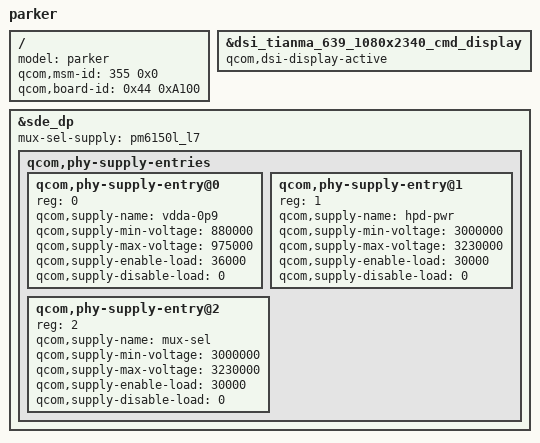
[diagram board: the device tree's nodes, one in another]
/* Copyright (c) 2019, The Linux Foundation. All rights reserved.
 *
 * This program is free software; you can redistribute it and/or modify
 * it under the terms of the GNU General Public License version 2 and
 * only version 2 as published by the Free Software Foundation.
 *
 * This program is distributed in the hope that it will be useful,
 * but WITHOUT ANY WARRANTY; without even the implied warranty of
 * MERCHANTABILITY or FITNESS FOR A PARTICULAR PURPOSE.  See the
 * GNU General Public License for more details.
 */

/dts-v1/;
/plugin/;

#include <dt-bindings/interrupt-controller/arm-gic.h>
#include <dt-bindings/clock/qcom,camcc-sm6150.h>

#include "sm6150-parker-common-overlay.dtsi"

/ {
	model = "parker";
	qcom,msm-id = <355 0x0>;
	qcom,board-id = <0x44 0xA100>;
};

&dsi_tianma_639_1080x2340_cmd_display {
	qcom,dsi-display-active;
};

&sde_dp {
	/delete-property/qcom,phy-supply-entries;

	mux-sel-supply = <&pm6150l_l7>;

	qcom,phy-supply-entries {
		#address-cells = <1>;
		#size-cells = <0>;
		qcom,phy-supply-entry@0 {
			reg = <0>;
			qcom,supply-name = "vdda-0p9";
			qcom,supply-min-voltage = <880000>;
			qcom,supply-max-voltage = <975000>;
			qcom,supply-enable-load = <36000>;
			qcom,supply-disable-load = <0>;
		};
		qcom,phy-supply-entry@1 {
			reg = <1>;
			qcom,supply-name = "hpd-pwr";
			qcom,supply-min-voltage = <3000000>;
			qcom,supply-max-voltage = <3230000>;
			qcom,supply-enable-load = <30000>;
			qcom,supply-disable-load = <0>;
		};
		qcom,phy-supply-entry@2 {
			reg = <2>;
			qcom,supply-name = "mux-sel";
			qcom,supply-min-voltage = <3000000>;
			qcom,supply-max-voltage = <3230000>;
			qcom,supply-enable-load = <30000>;
			qcom,supply-disable-load = <0>;
		};
	};
};
